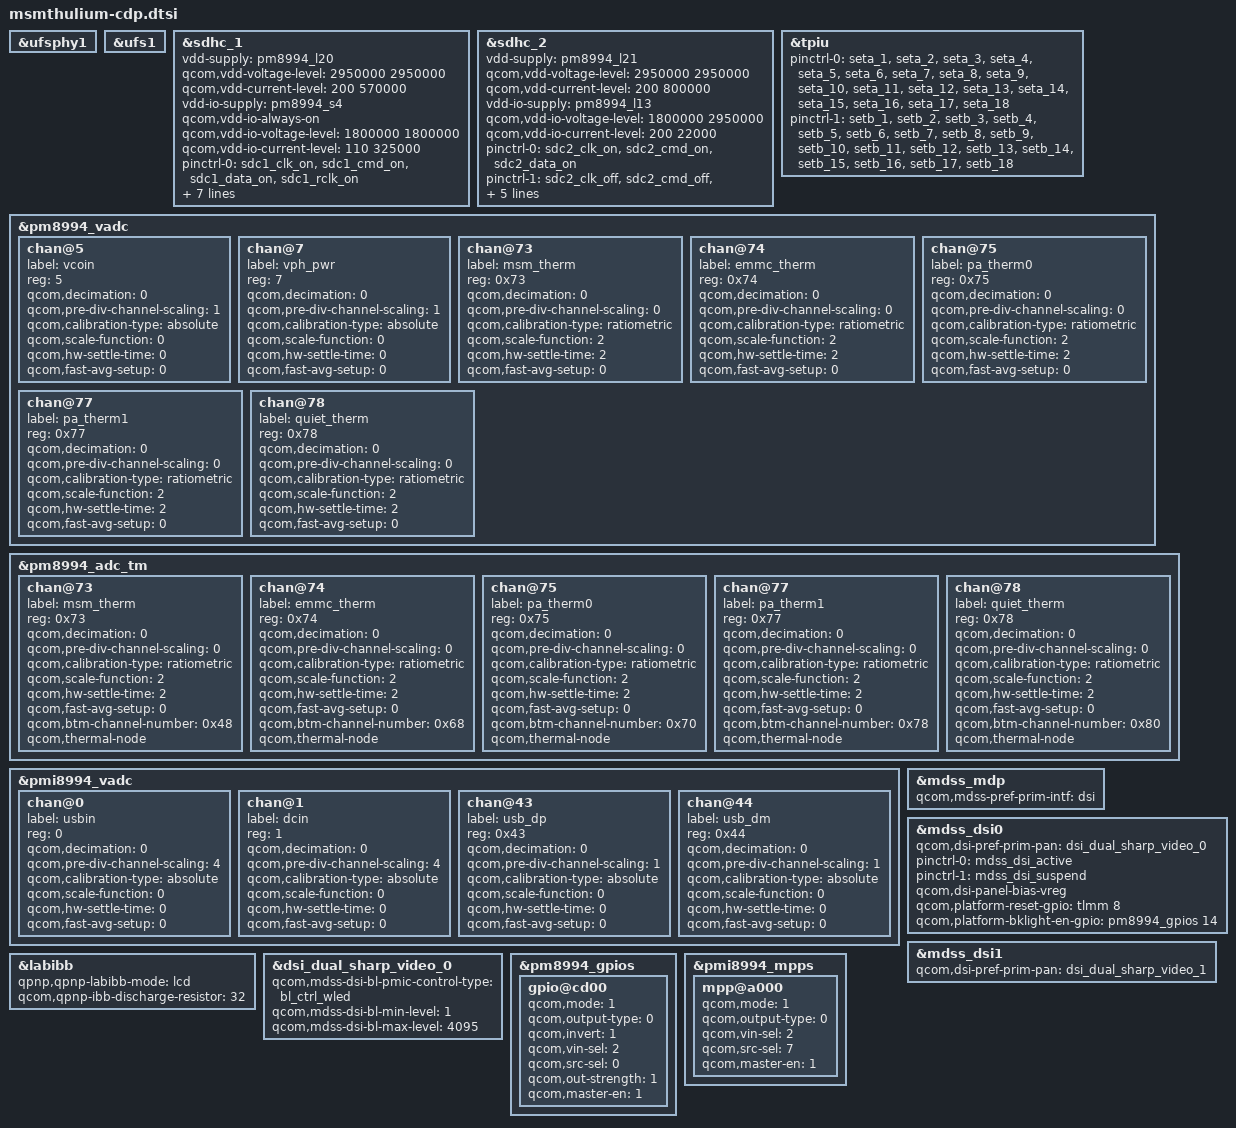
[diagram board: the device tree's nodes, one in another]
/* Copyright (c) 2015, The Linux Foundation. All rights reserved.
 *
 * This program is free software; you can redistribute it and/or modify
 * it under the terms of the GNU General Public License version 2 and
 * only version 2 as published by the Free Software Foundation.
 *
 * This program is distributed in the hope that it will be useful,
 * but WITHOUT ANY WARRANTY; without even the implied warranty of
 * MERCHANTABILITY or FITNESS FOR A PARTICULAR PURPOSE.  See the
 * GNU General Public License for more details.
 */

#include "msmthulium-pinctrl.dtsi"
#include "msmthulium-camera-sensor-cdp.dtsi"

&ufsphy1 {
	status = "ok";
};

&ufs1 {
	status = "ok";
};

&sdhc_1 {
	vdd-supply = <&pm8994_l20>;
	qcom,vdd-voltage-level = <2950000 2950000>;
	qcom,vdd-current-level = <200 570000>;

	vdd-io-supply = <&pm8994_s4>;
	qcom,vdd-io-always-on;
	qcom,vdd-io-voltage-level = <1800000 1800000>;
	qcom,vdd-io-current-level = <110 325000>;

	pinctrl-names = "active", "sleep";
	pinctrl-0 = <&sdc1_clk_on &sdc1_cmd_on &sdc1_data_on &sdc1_rclk_on>;
	pinctrl-1 = <&sdc1_clk_off &sdc1_cmd_off &sdc1_data_off &sdc1_rclk_off>;

	qcom,clk-rates = <400000 20000000 25000000 50000000 96000000 192000000 384000000>;
	qcom,nonremovable;
	qcom,bus-speed-mode = "HS400_1p8v", "HS200_1p8v", "DDR_1p8v";

	status = "ok";
};

&sdhc_2 {
	vdd-supply = <&pm8994_l21>;
	qcom,vdd-voltage-level = <2950000 2950000>;
	qcom,vdd-current-level = <200 800000>;

	vdd-io-supply = <&pm8994_l13>;
	qcom,vdd-io-voltage-level = <1800000 2950000>;
	qcom,vdd-io-current-level = <200 22000>;

	pinctrl-names = "active", "sleep";
	pinctrl-0 = <&sdc2_clk_on  &sdc2_cmd_on &sdc2_data_on>;
	pinctrl-1 = <&sdc2_clk_off &sdc2_cmd_off &sdc2_data_off>;

	qcom,clk-rates = <400000 20000000 25000000 50000000 100000000 200000000>;
	qcom,bus-speed-mode = "SDR12", "SDR25", "SDR50", "DDR50", "SDR104";

	status = "ok";
};

/* CoreSight */
&tpiu {
	pinctrl-names = "seta-pctrl", "setb-pctrl";
	pinctrl-0 = <&seta_1 &seta_2 &seta_3 &seta_4 &seta_5 &seta_6 &seta_7
		     &seta_8 &seta_9 &seta_10 &seta_11 &seta_12 &seta_13
		     &seta_14 &seta_15 &seta_16 &seta_17 &seta_18>;
	pinctrl-1 = <&setb_1 &setb_2 &setb_3 &setb_4 &setb_5 &setb_6 &setb_7
		     &setb_8 &setb_9 &setb_10 &setb_11 &setb_12 &setb_13
		     &setb_14 &setb_15 &setb_16 &setb_17 &setb_18>;
};

&pm8994_vadc {
	chan@5 {
		label = "vcoin";
		reg = <5>;
		qcom,decimation = <0>;
		qcom,pre-div-channel-scaling = <1>;
		qcom,calibration-type = "absolute";
		qcom,scale-function = <0>;
		qcom,hw-settle-time = <0>;
		qcom,fast-avg-setup = <0>;
	};

	chan@7 {
		label = "vph_pwr";
		reg = <7>;
		qcom,decimation = <0>;
		qcom,pre-div-channel-scaling = <1>;
		qcom,calibration-type = "absolute";
		qcom,scale-function = <0>;
		qcom,hw-settle-time = <0>;
		qcom,fast-avg-setup = <0>;
	};

	chan@73 {
		label = "msm_therm";
		reg = <0x73>;
		qcom,decimation = <0>;
		qcom,pre-div-channel-scaling = <0>;
		qcom,calibration-type = "ratiometric";
		qcom,scale-function = <2>;
		qcom,hw-settle-time = <2>;
		qcom,fast-avg-setup = <0>;
	};

	chan@74 {
		label = "emmc_therm";
		reg = <0x74>;
		qcom,decimation = <0>;
		qcom,pre-div-channel-scaling = <0>;
		qcom,calibration-type = "ratiometric";
		qcom,scale-function = <2>;
		qcom,hw-settle-time = <2>;
		qcom,fast-avg-setup = <0>;
	};

	chan@75 {
		label = "pa_therm0";
		reg = <0x75>;
		qcom,decimation = <0>;
		qcom,pre-div-channel-scaling = <0>;
		qcom,calibration-type = "ratiometric";
		qcom,scale-function = <2>;
		qcom,hw-settle-time = <2>;
		qcom,fast-avg-setup = <0>;
	};

	chan@77 {
		label = "pa_therm1";
		reg = <0x77>;
		qcom,decimation = <0>;
		qcom,pre-div-channel-scaling = <0>;
		qcom,calibration-type = "ratiometric";
		qcom,scale-function = <2>;
		qcom,hw-settle-time = <2>;
		qcom,fast-avg-setup = <0>;
	};

	chan@78 {
		label = "quiet_therm";
		reg = <0x78>;
		qcom,decimation = <0>;
		qcom,pre-div-channel-scaling = <0>;
		qcom,calibration-type = "ratiometric";
		qcom,scale-function = <2>;
		qcom,hw-settle-time = <2>;
		qcom,fast-avg-setup = <0>;
	};
};

&pm8994_adc_tm {
	chan@73 {
		label = "msm_therm";
		reg = <0x73>;
		qcom,decimation = <0>;
		qcom,pre-div-channel-scaling = <0>;
		qcom,calibration-type = "ratiometric";
		qcom,scale-function = <2>;
		qcom,hw-settle-time = <2>;
		qcom,fast-avg-setup = <0>;
		qcom,btm-channel-number = <0x48>;
		qcom,thermal-node;
	};

	chan@74 {
		label = "emmc_therm";
		reg = <0x74>;
		qcom,decimation = <0>;
		qcom,pre-div-channel-scaling = <0>;
		qcom,calibration-type = "ratiometric";
		qcom,scale-function = <2>;
		qcom,hw-settle-time = <2>;
		qcom,fast-avg-setup = <0>;
		qcom,btm-channel-number = <0x68>;
		qcom,thermal-node;
	};

	chan@75 {
		label = "pa_therm0";
		reg = <0x75>;
		qcom,decimation = <0>;
		qcom,pre-div-channel-scaling = <0>;
		qcom,calibration-type = "ratiometric";
		qcom,scale-function = <2>;
		qcom,hw-settle-time = <2>;
		qcom,fast-avg-setup = <0>;
		qcom,btm-channel-number = <0x70>;
		qcom,thermal-node;
	};

	chan@77 {
		label = "pa_therm1";
		reg = <0x77>;
		qcom,decimation = <0>;
		qcom,pre-div-channel-scaling = <0>;
		qcom,calibration-type = "ratiometric";
		qcom,scale-function = <2>;
		qcom,hw-settle-time = <2>;
		qcom,fast-avg-setup = <0>;
		qcom,btm-channel-number = <0x78>;
		qcom,thermal-node;
	};

	chan@78 {
		label = "quiet_therm";
		reg = <0x78>;
		qcom,decimation = <0>;
		qcom,pre-div-channel-scaling = <0>;
		qcom,calibration-type = "ratiometric";
		qcom,scale-function = <2>;
		qcom,hw-settle-time = <2>;
		qcom,fast-avg-setup = <0>;
		qcom,btm-channel-number = <0x80>;
		qcom,thermal-node;
	};
};

&pmi8994_vadc {
	chan@0 {
		label = "usbin";
		reg = <0>;
		qcom,decimation = <0>;
		qcom,pre-div-channel-scaling = <4>;
		qcom,calibration-type = "absolute";
		qcom,scale-function = <0>;
		qcom,hw-settle-time = <0>;
		qcom,fast-avg-setup = <0>;
	};

	chan@1 {
		label = "dcin";
		reg = <1>;
		qcom,decimation = <0>;
		qcom,pre-div-channel-scaling = <4>;
		qcom,calibration-type = "absolute";
		qcom,scale-function = <0>;
		qcom,hw-settle-time = <0>;
		qcom,fast-avg-setup = <0>;
	};

	chan@43 {
		label = "usb_dp";
		reg = <0x43>;
		qcom,decimation = <0>;
		qcom,pre-div-channel-scaling = <1>;
		qcom,calibration-type = "absolute";
		qcom,scale-function = <0>;
		qcom,hw-settle-time = <0>;
		qcom,fast-avg-setup = <0>;
	};

	chan@44 {
		label = "usb_dm";
		reg = <0x44>;
		qcom,decimation = <0>;
		qcom,pre-div-channel-scaling = <1>;
		qcom,calibration-type = "absolute";
		qcom,scale-function = <0>;
		qcom,hw-settle-time = <0>;
		qcom,fast-avg-setup = <0>;
	};
};

#include "dsi-panel-sharp-dualmipi0-wqxga-video.dtsi"
#include "dsi-panel-sharp-dualmipi1-wqxga-video.dtsi"

&mdss_mdp {
	qcom,mdss-pref-prim-intf = "dsi";
};

&mdss_dsi0 {
	qcom,dsi-pref-prim-pan = <&dsi_dual_sharp_video_0>;
	pinctrl-names = "mdss_default", "mdss_sleep";
	pinctrl-0 = <&mdss_dsi_active>;
	pinctrl-1 = <&mdss_dsi_suspend>;
	qcom,dsi-panel-bias-vreg;
	qcom,platform-reset-gpio = <&tlmm 8 0>;
	qcom,platform-bklight-en-gpio = <&pm8994_gpios 14 0>;
};

&mdss_dsi1 {
	qcom,dsi-pref-prim-pan = <&dsi_dual_sharp_video_1>;
};

&labibb {
	status = "ok";
	qpnp,qpnp-labibb-mode = "lcd";
	qcom,qpnp-ibb-discharge-resistor = <32>;
};

&dsi_dual_sharp_video_0 {
	qcom,mdss-dsi-bl-pmic-control-type = "bl_ctrl_wled";
	qcom,mdss-dsi-bl-min-level = <1>;
	qcom,mdss-dsi-bl-max-level = <4095>;
};

&pm8994_gpios {
	gpio@cd00 { /* lcd_bklt_reg_en */
		qcom,mode = <1>;	/* DIGITAL OUT */
		qcom,output-type = <0>;		/* CMOS logic */
		qcom,invert = <1>; 	/* output hight initially */
		qcom,vin-sel = <2>;	/* 1.8 */
		qcom,src-sel = <0>;	/* CONSTANT */
		qcom,out-strength = <1>;	/* Low drive strength */
		qcom,master-en = <1>;	/* ENABLE GPIO */
		status = "okay";
	};
};

&pmi8994_mpps {
	mpp@a000 { /* MPP 1 */
		qcom,mode = <1>;                /* Digital output */
		qcom,output-type = <0>;         /* CMOS logic */
		qcom,vin-sel = <2>;             /* S4 1.8V */
		qcom,src-sel = <7>;             /* DTEST4 */
		qcom,master-en = <1>;           /* Enable MPP */
		status = "okay";
	};
};
